# STM32H723 register map
File version: 1.6
CPU: CM7 r0p1, little endian, MPU, FPU, 4 interrupt priority bits
Registers are 32-bit, read-write, reset 0x0 unless marked. A register's access mark holds for its fields unless they carry their own. Offsets are from the block's base; [hi:lo] are bit positions; 'fields as' and 'values as' point back to an identical list.

## FLASH
Base 0x52002000
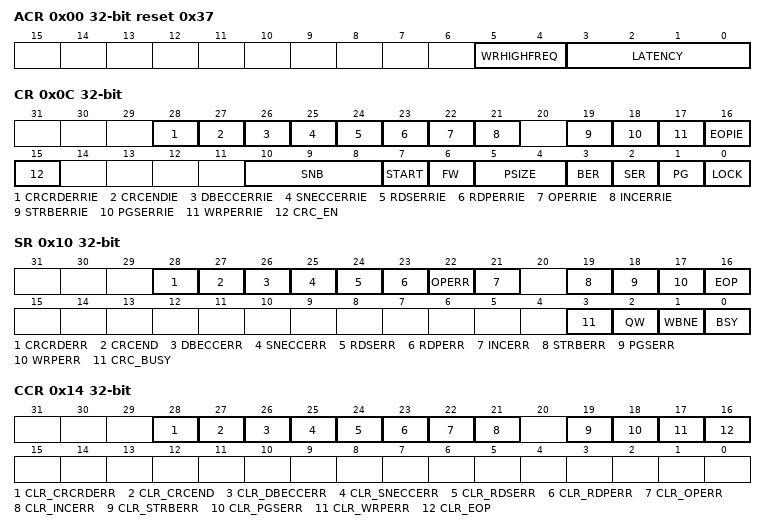
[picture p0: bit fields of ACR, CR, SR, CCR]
0x00 ACR reset 0x37 — Access control register
  [5:4] WRHIGHFREQ — Flash signal delay
  [3:0] LATENCY — Read latency
0x04 KEYR — FLASH key register
  [31:0] KEYKEYRR — access configuration unlock key
0x08 OPTKEYR wo — FLASH option key register
  [31:0] OPTKEYR — Unlock key option bytes
0x0C CR — FLASH control register
  [28] CRCRDERRIE — CRC read error interrupt enable bit When CRCRDERRIE1 bit is set to 1, an interrupt is generated when a protected area (PCROP or secure-only) has been detected during the last CRC computation on bank 1. CRCRDERRIE1 can be programmed only when LOCK1 is cleared to 0.
  [27] CRCENDIE — end of CRC calculation interrupt enable bit
  [26] DBECCERRIE — ECC double detection error interrupt enable bit
  [25] SNECCERRIE — ECC single correction error interrupt enable bit
  [24] RDSERRIE — secure error interrupt enable bit
  [23] RDPERRIE — read protection error interrupt enable bit
  [22] OPERRIE — write/erase error interrupt enable bit
  [21] INCERRIE — inconsistency error interrupt enable bit
  [19] STRBERRIE — strobe error interrupt enable bit
  [18] PGSERRIE — programming sequence error interrupt enable bit
  [17] WRPERRIE — write protection error interrupt enable bit
  [16] EOPIE — end-of-program interrupt control bit
  [15] CRC_EN — CRC control bit
  [10:8] SNB — sector erase selection number
  [7] START — bank or sector erase start control bit
  [6] FW — write forcing control bit
  [5:4] PSIZE — program size
  [3] BER — erase request
  [2] SER — sector erase request
  [1] PG — program enable bit
  [0] LOCK — configuration lock bit
0x10 SR — FLASH status register for bank 1
  [28] CRCRDERR ro — CRC read error flag CRCRDERR1 flag is raised when a word is found read protected during a CRC operation on bank 1. An interrupt is generated if CRCRDIE1 and CRCEND1 are set to 1. Writing 1 to CLR_CRCRDERR1 bit in FLASH_CCR1 register clears CRCRDERR1. Note: This flag is valid only when CRCEND1 bit is set to 1
  [27] CRCEND — CRC-complete flag
  [26] DBECCERR — ECC double detection error flag
  [25] SNECCERR — single correction error flag
  [24] RDSERR — secure error flag
  [23] RDPERR — read protection error flag
  [22] OPERR — write/erase error flag
  [21] INCERR — inconsistency error flag
  [19] STRBERR — strobe error flag
  [18] PGSERR — programming sequence error flag
  [17] WRPERR — write protection error flag
  [16] EOP — end-of-program flag
  [3] CRC_BUSY — CRC busy flag
  [2] QW — wait queue flag
  [1] WBNE — write buffer not empty flag
  [0] BSY — ongoing program flag
0x14 CCR — FLASH clear control register for bank 1
  [28] CLR_CRCRDERR wo — CRCRDERR1 flag clear bit Setting this bit to 1 resets to 0 CRCRDERR1 flag in FLASH_SR1 register.
  [27] CLR_CRCEND — CRCEND flag clear bit
  [26] CLR_DBECCERR — DBECCERR flag clear bit
  [25] CLR_SNECCERR — SNECCERR flag clear bit
  [24] CLR_RDSERR — RDSERR flag clear bit
  [23] CLR_RDPERR — RDPERR flag clear bit
  [22] CLR_OPERR — OPERR flag clear bit
  [21] CLR_INCERR — INCERR flag clear bit
  [19] CLR_STRBERR — STRBERR flag clear bit
  [18] CLR_PGSERR — PGSERR flag clear bi
  [17] CLR_WRPERR — WRPERR1 flag clear bit
  [16] CLR_EOP — EOP1 flag clear bit
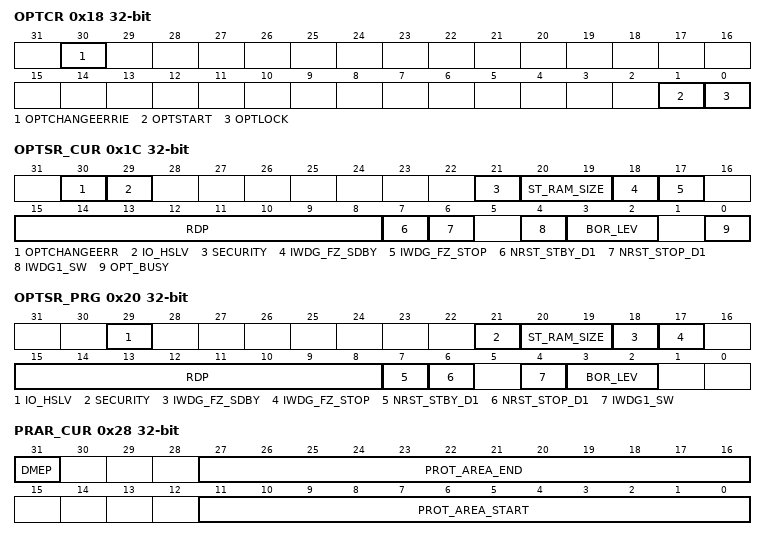
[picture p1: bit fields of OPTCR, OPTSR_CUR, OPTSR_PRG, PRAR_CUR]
0x18 OPTCR — FLASH option control register
  [30] OPTCHANGEERRIE — Option byte change error interrupt enable bit
  [1] OPTSTART — Option byte start change option configuration bit
  [0] OPTLOCK — FLASH_OPTCR lock option configuration bit
0x1C OPTSR_CUR — FLASH option status register
  [30] OPTCHANGEERR — Option byte change error flag
  [29] IO_HSLV — I/O high-speed at low-voltage status bit (PRODUCT_BELOW_25V)
  [21] SECURITY — Security enable option status bit
  [20:19] ST_RAM_SIZE — DTCM RAM size option status
  [18] IWDG_FZ_SDBY — IWDG Standby mode freeze option status bit
  [17] IWDG_FZ_STOP — IWDG Stop mode freeze option status bit
  [15:8] RDP — Readout protection level option status byte
  [7] NRST_STBY_D1 — D1 DStandby entry reset option status bit
  [6] NRST_STOP_D1 — D1 DStop entry reset option status bit
  [4] IWDG1_SW — IWDG1 control option status bit
  [3:2] BOR_LEV — Brownout level option status bit
  [0] OPT_BUSY — Option byte change ongoing flag
0x20 OPTSR_PRG — FLASH option status register
  [29] IO_HSLV — I/O high-speed at low-voltage (PRODUCT_BELOW_25V)
  [21] SECURITY — Security option configuration bit
  [20:19] ST_RAM_SIZE — DTCM size select option configuration bits
  [18] IWDG_FZ_SDBY — IWDG Standby mode freeze option configuration bit
  [17] IWDG_FZ_STOP — IWDG Stop mode freeze option configuration bit
  [15:8] RDP — Readout protection level option configuration byte
  [7] NRST_STBY_D1 — Option byte erase after D1 DStandby option configuration bit
  [6] NRST_STOP_D1 — Option byte erase after D1 DStop option configuration bit
  [4] IWDG1_SW — IWDG1 option configuration bit
  [3:2] BOR_LEV — BOR reset level option configuration bits
0x24 OPTCCR wo — FLASH option clear control register
  [30] CLR_OPTCHANGEERR — OPTCHANGEERR reset bit
0x28 PRAR_CUR ro — FLASH protection address for bank 1
  [31] DMEP — PCROP protected erase enable option status bit
  [27:16] PROT_AREA_END — highest PCROP protected address
  [11:0] PROT_AREA_START — lowest PCROP protected address
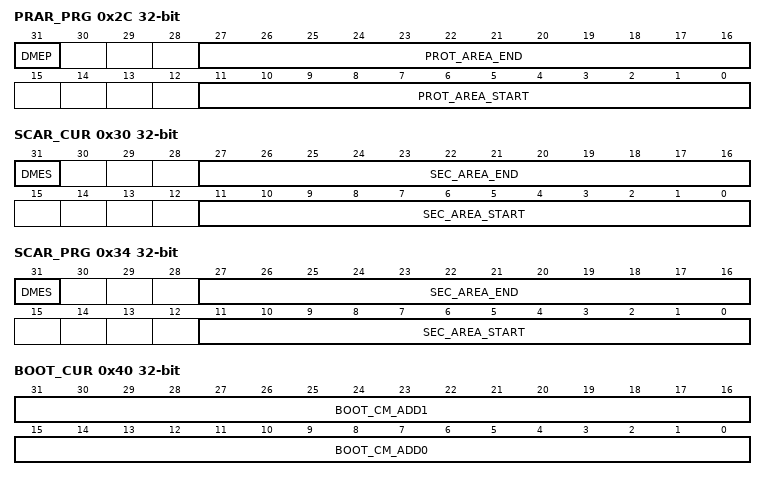
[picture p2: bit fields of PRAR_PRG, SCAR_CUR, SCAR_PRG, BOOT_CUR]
0x2C PRAR_PRG — FLASH protection address for bank 1
  [31] DMEP — PCROP protected erase enable option configuration bit
  [27:16] PROT_AREA_END — highest PCROP protected address configuration
  [11:0] PROT_AREA_START — lowest PCROP protected address configuration
0x30 SCAR_CUR — FLASH secure address for bank 1
  [31] DMES — secure protected erase enable option status bit
  [27:16] SEC_AREA_END — highest secure protected address
  [11:0] SEC_AREA_START — lowest secure protected address
0x34 SCAR_PRG — FLASH secure address for bank 1
  [31] DMES — secure protected erase enable option configuration bit
  [27:16] SEC_AREA_END — highest secure protected address configuration
  [11:0] SEC_AREA_START — lowest secure protected address configuration
0x38 WPSN_CUR ro — FLASH write sector protection for bank 1
  [7:0] WRPSn — sector write protection option status byte
0x3C WPSN_PRG — FLASH write sector protection for bank 1
  [7:0] WRPSn — sector write protection configuration byte
0x40 BOOT_CUR ro — FLASH register with boot address
  [31:16] BOOT_CM_ADD1 — Boot address 1
  [15:0] BOOT_CM_ADD0 — Boot address 0
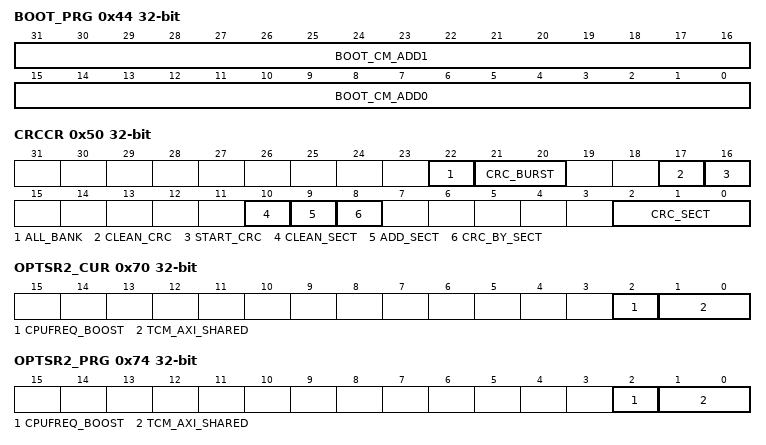
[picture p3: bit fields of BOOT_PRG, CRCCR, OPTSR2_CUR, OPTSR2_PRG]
0x44 BOOT_PRG ro — FLASH register with boot address
  fields as BOOT_CUR
0x50 CRCCR — FLASH CRC control register for bank 1
  [22] ALL_BANK wo — Bank 1 CRC select bit
  [21:20] CRC_BURST — CRC burst size
  [17] CLEAN_CRC — CRC clear bit
  [16] START_CRC — CRC start bit
  [10] CLEAN_SECT — CRC sector list clear bit
  [9] ADD_SECT — CRC sector select bit
  [8] CRC_BY_SECT — CRC sector mode select bit
  [2:0] CRC_SECT — CRC sector number
0x54 CRCSADDR — FLASH CRC start address register for bank 1
  [19:2] CRC_START_ADDR — CRC start address on bank 1
0x58 CRCEADDR — FLASH CRC end address register for bank 1
  [19:2] CRC_END_ADDR — CRC end address on bank 1
0x5C CRCDATAR — FLASH CRC data register
  [31:0] CRC_DATA — CRC result
0x60 ECC_FAR ro — FLASH ECC fail address for bank 1
  [14:0] FAIL_ECC_ADDR — ECC error address
0x70 OPTSR2_CUR ro — FLASH ECC fail address for bank 1
  [2] CPUFREQ_BOOST — CPU frequency boost status bit
  [1:0] TCM_AXI_SHARED — TCM RAM sharing status bit
0x74 OPTSR2_PRG — FLASH ECC fail address for bank 1
  fields as OPTSR2_CUR
